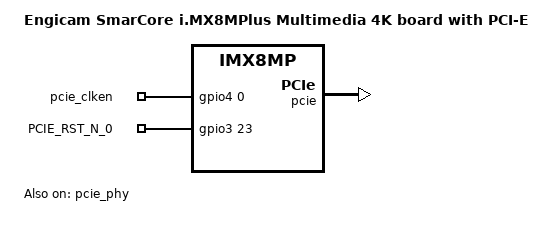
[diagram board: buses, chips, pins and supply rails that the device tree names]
// SPDX-License-Identifier: (GPL-2.0+ OR MIT)
/*
 * Copyright 2022 Engicam
 */

/dts-v1/;

#include "imx8mp-smarcore-multimedia-4k.dts"

/ {
	model = "Engicam SmarCore i.MX8MPlus Multimedia 4K board with PCI-E";
	compatible = "engi,imx8-smarcore", "fsl,imx8mp";
  
	gpio_export {
		compatible = "gpio-export";
		#size-cells = <0>;
    PCIe_CLKEN
		{
			gpio-export,name = "pcie_clken";
			gpio-export,output = <1>;
			gpios = <&gpio4 0 0>;
		};

		PCIE_RST_N_0
		{
			gpio-export,name = "PCIE_RST_N_0";
			gpio-export,output = <0>;
			gpios = <&gpio3 23 0>;
		};
	};
};

&pcie {
	pinctrl-names = "default";
	pinctrl-0 = <&pinctrl_pcie>;
	ext_osc = <1>;
	clocks = <&clk IMX8MP_CLK_HSIO_ROOT>,
		 <&clk IMX8MP_CLK_PCIE_AUX>,
		 <&clk IMX8MP_CLK_HSIO_AXI>,
		 <&clk IMX8MP_CLK_PCIE_ROOT>;
	clock-names = "pcie", "pcie_aux", "pcie_phy", "pcie_bus";
	assigned-clocks = <&clk IMX8MP_CLK_HSIO_AXI_SRC>,
			  <&clk IMX8MP_CLK_PCIE_AUX>;
//	assigned-clock-rates = <500000000>, <10000000>;
	assigned-clock-parents = <&clk IMX8MP_SYS_PLL2_500M>,
				 <&clk IMX8MP_SYS_PLL2_50M>;
	l1ss-disabled;
	status = "okay";
};

&pcie_phy {
	ext_osc = <1>;
	status = "okay";
};

&iomuxc {
	
	pinctrl-names = "default";
	pinctrl-0 = <&pinctrl_hog>;
	pinctrl_hog: hoggrp {
		fsl,pins = <
			MX8MP_IOMUXC_SAI5_RXD2__GPIO3_IO23		0x19 // PCIE_RST_N_0
		>;
	};
	
	pinctrl_pcie: pciegrp {
		fsl,pins = <
			MX8MP_IOMUXC_I2C4_SCL__PCIE_CLKREQ_B		0x61 /* open drain, pull up */
			MX8MP_IOMUXC_SAI1_RXFS__GPIO4_IO00		0x41
		>;
	};
};
